# PT32G031xx register map
File version: 0.4
Registers are 32-bit, read-write, reset 0x0 unless marked. A register's access mark holds for its fields unless they carry their own. Offsets are from the block's base; lines under a group give offsets from that group; [hi:lo] are bit positions; {n}, {i} and the like mark numbered series; 'fields as' and 'values as' point back to an identical list; <NAME> marks a mode.

## Memory map
0x40000000 IFMC size 0x2000 — On-chip flash memory controller
0x40000800 CMP0 size 0x400
0x40000C00 CMP1 size 0x400
0x40001000 TIM2 size 0x400 — Basic timer
0x40001400 TIM3 size 0x400 — Basic timer
0x40001C00 TIM4 size 0x400 — Low power timer
0x40003000 IWDG size 0x400 — Independent Watchdog
0x40003C00 CRC size 0x400 — Cyclic redundancy check
0x40004400 UART0 size 0x400 — Universal Asynchronous Receiver Transmitter
0x40005400 I2C0 size 0x400 — Inter－Integrated Circuit
0x40006400 TIM8 size 0x400 — Advanced timer
0x4000F000 DMA size 0x400 — Direct memory access
0x40012400 ADC size 0x400 — Analog-to-digital converters
0x40012C00 TIM1 size 0x400 — Advanced timer
0x40013000 SPI0 size 0x400 — Serial peripheral interface
0x40014000 LDAC size 0x400
0x40015C00 OPA0 size 0x400
0x40015D00 OPA1 size 0x400
0x40020000 RCC size 0x400 — Reset and clock control
0x40020400 PWR size 0x400 — Power control
0x40020800 ES size 0x400 — Device Electronic Signature
0x40020C00 SYSCFG size 0x400 — System Configuration
0x40030000 ALU size 0x400 — Arithmetic Logic Unit
0x48000000 GPIOA size 0x400 — General purpose I/O
0x48000100 AFIOA size 0x400 — Alternate function
0x48000200 EXTIA size 0x400 — External interrupt
0x48001000 GPIOB size 0x400
0x48001100 AFIOB size 0x400
0x48001200 EXTIB size 0x400

## CRC — Cyclic redundancy check
Base 0x40003C00
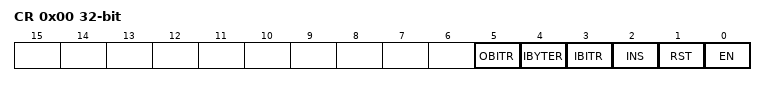
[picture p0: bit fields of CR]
0x00 CR access per field — Control Register
  [5] OBITR rw — CRC output bit sequence reversal
  [4] IBYTER rw — CRC input byte sequence reversal
  [3] IBITR rw — CRC input bit sequence reversal
  [2] INS rw — CRC input selection
  [1] RST wo — CRC reset control
  [0] EN rw — CRC enable
0x04 SEEDR reset 0xFFFF — Seed Register
  [15:0] SEED — CRC seed
0x08 POLYR reset 0x8005 — Polynomial Register
  [15:0] POLY — CRC poly
0x0C DINR wo — Data Input Register
  [15:0] DIN — CRC data input
0x10 DOUT ro — Data Output Register
  [15:0] DOUT — CRC data output

## PWR — Power control
Base 0x40020400
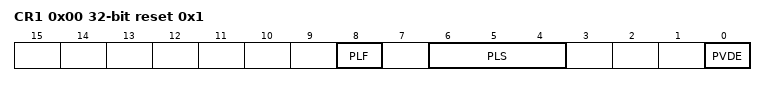
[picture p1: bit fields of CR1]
0x00 CR1 access per field reset 0x1 — Control Register 1
  [8] PLF ro — PVD level status flag
  [6:4] PLS rw — PVD level selection
  [0] PVDE rw — Power voltage detection enable

## RCC — Reset and clock control
Base 0x40020000
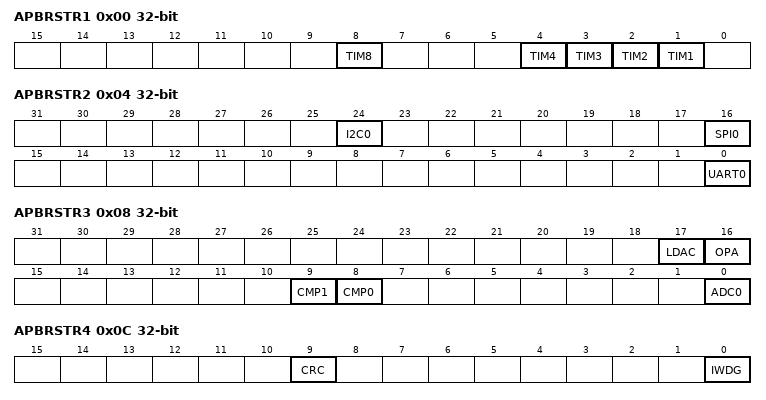
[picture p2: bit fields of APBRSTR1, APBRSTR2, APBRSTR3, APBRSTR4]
0x00 APBRSTR1 — APB Peripheral Reset Register 1
  [8] TIM8 — TIM8 reset
  [n] TIM{n} (n=1..4) — TIM{n} reset
0x04 APBRSTR2 — APB Peripheral Reset Register 2
  [24] I2C0 — I2C0 reset
  [16] SPI0 — SPI0 reset
  [0] UART0 — UART0 reset
0x08 APBRSTR3 — APB Peripheral Reset Register 3
  [17] LDAC — LDAC reset
  [16] OPA — OPA reset
  [9] CMP1 — CMP1 reset
  [8] CMP0 — CMP0 reset
  [0] ADC0 — ADC0 reset
0x0C APBRSTR4 — APB Peripheral Reset Register 4
  [9] CRC — CRC reset
  [0] IWDG — IWDG reset
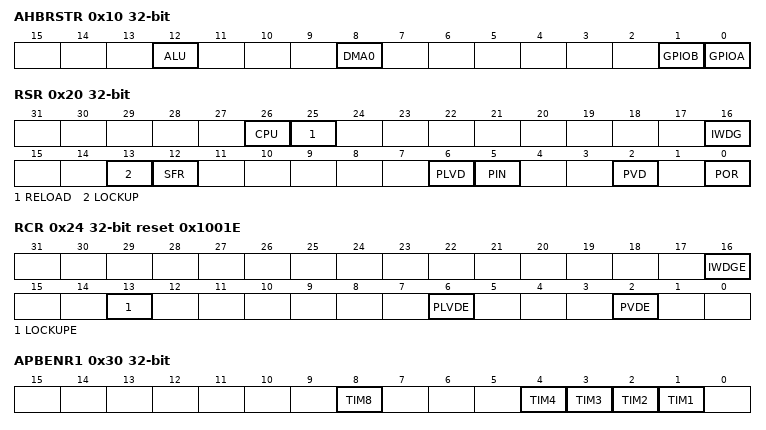
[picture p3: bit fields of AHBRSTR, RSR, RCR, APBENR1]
0x10 AHBRSTR — AHB Peripheral Reset Register
  [12] ALU — ALU reset
  [8] DMA0 — DMA0 reset
  [1] GPIOB — GPIOB reset
  [0] GPIOA — GPIOA reset
0x20 RSR — Reset Status Register
  [26] CPU — CPU core reset flag
  [25] RELOAD — Reload reset flag
  [16] IWDG — IWDG reset flag
  [13] LOCKUP — LOCKUP reset flag
  [12] SFR — Software reset flag
  [6] PLVD — Power low voltage detection reset flag
  [5] PIN — Pin reset flag
  [2] PVD — PVD reset flag
  [0] POR — Power reset flag
0x24 RCR reset 0x1001E — Reset Control Register
  [16] IWDGE — IWDG reset enable
  [13] LOCKUPE — LOCKUP reset enable
  [6] PLVDE — Power low voltage detection reset enable
  [2] PVDE — PVD reset enable
0x28 ASRCR wo — Advanced Software Reset Control Register
  [15:0] KEY
0x30 APBENR1 — APB Peripheral Clock Enable Register 1
  [8] TIM8 — TIM8 clock enable
  [n] TIM{n} (n=1..4) — TIM{n} clock enable
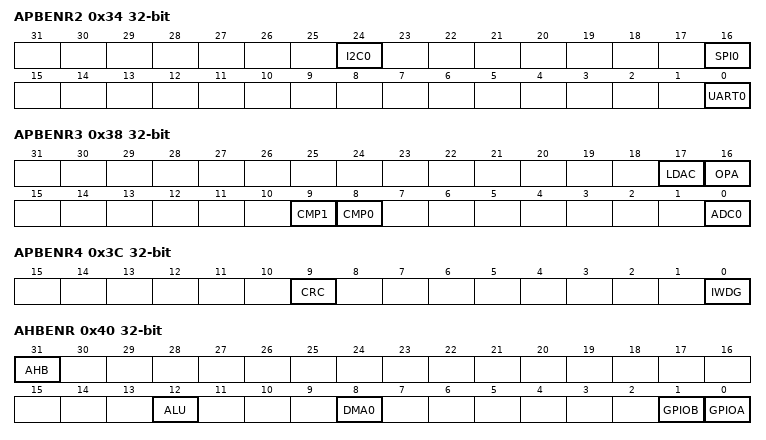
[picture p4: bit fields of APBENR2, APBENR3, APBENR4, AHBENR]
0x34 APBENR2 — APB Peripheral Clock Enable Register 2
  [24] I2C0 — I2C0 clock enable
  [16] SPI0 — SPI0 clock enable
  [0] UART0 — UART0 clock enable
0x38 APBENR3 — APB Peripheral Clock Enable Register 3
  [17] LDAC — LDAC clock enable
  [16] OPA — OPA clock enable
  [9] CMP1 — CMP1 clock enable
  [8] CMP0 — CMP0 clock enable
  [0] ADC0 — ADC0 clock enable
0x3C APBENR4 — APB Peripheral Clock Enable Register 4
  [9] CRC — CRC clock enable
  [0] IWDG — IWDG clock enable
0x40 AHBENR — AHB Peripheral Clock Enable Register
  [31] AHB — AHB clock enable
  [12] ALU — ALU clock enable
  [8] DMA0 — DMA0 clock enable
  [1] GPIOB — GPIOB clock enable
  [0] GPIOA — GPIOA clock enable
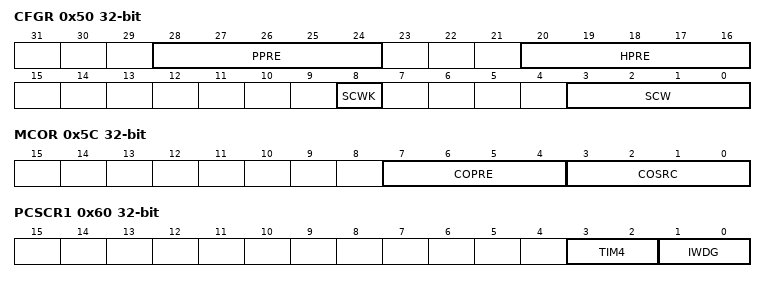
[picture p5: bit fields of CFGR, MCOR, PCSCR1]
0x50 CFGR — Clock Configuration Register
  [28:24] PPRE — PCLK prescaler
  [20:16] HPRE — HCLK prescaler
  [8] SCWK — System clock after wakeup
  [3:0] SCW — System clock switch
0x5C MCOR — MCO Control Register
  [7:4] COPRE — Clock output prescaler
  [3:0] COSRC — Clock output source
0x60 PCSCR1 — Peripheral Clock Source Configuration Register 1
  [3:2] TIM4 — TIM4 clock source selection
  [1:0] IWDG — IWDG clock source selection
0x74 LSICR reset 0x1 — LSI Control Register
  [0] EN — LSI enable
